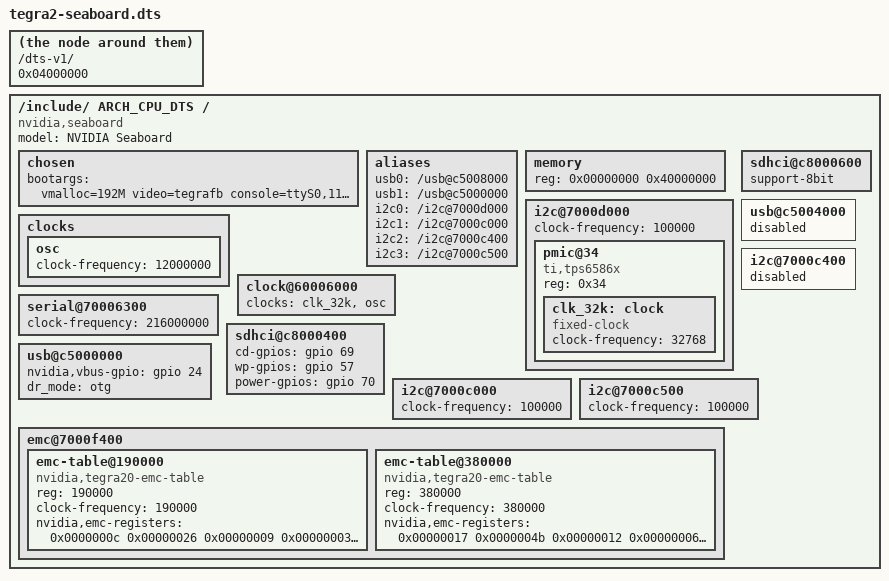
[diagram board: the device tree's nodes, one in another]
/dts-v1/;

/memreserve/ 0x1c000000 0x04000000;
/include/ ARCH_CPU_DTS

/ {
	model = "NVIDIA Seaboard";
	compatible = "nvidia,seaboard", "nvidia,tegra20";

	chosen {
		bootargs = "vmalloc=192M video=tegrafb console=ttyS0,115200n8 root=/dev/mmcblk1p3 rw rootwait";
	};

	aliases {
		/* This defines the order of our USB ports */
		usb0 = "/usb@c5008000";
		usb1 = "/usb@c5000000";

		i2c0 = "/i2c@7000d000";
		i2c1 = "/i2c@7000c000";
		i2c2 = "/i2c@7000c400";
		i2c3 = "/i2c@7000c500";
	};

	memory {
		device_type = "memory";
		reg = < 0x00000000 0x40000000 >;
	};

	/* This is not used in U-Boot, but is expected to be in kernel .dts */
	i2c@7000d000 {
		clock-frequency = <100000>;
		pmic@34 {
			compatible = "ti,tps6586x";
			reg = <0x34>;

			clk_32k: clock {
				compatible = "fixed-clock";
				/*
				 * leave out for now due to CPP:
				 * #clock-cells = <0>;
				 */
				clock-frequency = <32768>;
			};
		};
	};

	clocks {
		osc {
			clock-frequency = <12000000>;
		};
	};

	clock@60006000 {
		clocks = <&clk_32k &osc>;
	};

	serial@70006300 {
		clock-frequency = < 216000000 >;
	};

	sdhci@c8000400 {
		cd-gpios = <&gpio 69 0>; /* gpio PI5 */
		wp-gpios = <&gpio 57 0>; /* gpio PH1 */
		power-gpios = <&gpio 70 0>; /* gpio PI6 */
	};

	sdhci@c8000600 {
		support-8bit;
	};

	usb@c5000000 {
		nvidia,vbus-gpio = <&gpio 24 0>; /* PD0 */
		dr_mode = "otg";
	};

	usb@c5004000 {
		status = "disabled";
	};

	i2c@7000c000 {
		clock-frequency = <100000>;
	};

	i2c@7000c400 {
		status = "disabled";
	};

	i2c@7000c500 {
		clock-frequency = <100000>;
	};

	emc@7000f400 {
		emc-table@190000 {
			reg = < 190000 >;
			compatible = "nvidia,tegra20-emc-table";
			clock-frequency = < 190000 >;
			nvidia,emc-registers = < 0x0000000c 0x00000026
				0x00000009 0x00000003 0x00000004 0x00000004
				0x00000002 0x0000000c 0x00000003 0x00000003
				0x00000002 0x00000001 0x00000004 0x00000005
				0x00000004 0x00000009 0x0000000d 0x0000059f
				0x00000000 0x00000003 0x00000003 0x00000003
				0x00000003 0x00000001 0x0000000b 0x000000c8
				0x00000003 0x00000007 0x00000004 0x0000000f
				0x00000002 0x00000000 0x00000000 0x00000002
				0x00000000 0x00000000 0x00000083 0xa06204ae
				0x007dc010 0x00000000 0x00000000 0x00000000
				0x00000000 0x00000000 0x00000000 0x00000000 >;
		};
		emc-table@380000 {
			reg = < 380000 >;
			compatible = "nvidia,tegra20-emc-table";
			clock-frequency = < 380000 >;
			nvidia,emc-registers = < 0x00000017 0x0000004b
				0x00000012 0x00000006 0x00000004 0x00000005
				0x00000003 0x0000000c 0x00000006 0x00000006
				0x00000003 0x00000001 0x00000004 0x00000005
				0x00000004 0x00000009 0x0000000d 0x00000b5f
				0x00000000 0x00000003 0x00000003 0x00000006
				0x00000006 0x00000001 0x00000011 0x000000c8
				0x00000003 0x0000000e 0x00000007 0x0000000f
				0x00000002 0x00000000 0x00000000 0x00000002
				0x00000000 0x00000000 0x00000083 0xe044048b
				0x007d8010 0x00000000 0x00000000 0x00000000
				0x00000000 0x00000000 0x00000000 0x00000000 >;
		};
	};
};
